# ATSAM4LC4A register map
Vendor: Atmel Corporation; Series: SAM4L; File version: B
CPU: CM4 r0p1, little endian, MPU, no FPU, 4 interrupt priority bits
Registers are 32-bit, write-only, reset 0x0 unless marked. A register's access mark holds for its fields unless they carry their own. Offsets are from the block's base; [hi:lo] are bit positions; {n}, {i} and the like mark numbered series.

## ABDACB — Audio Bitstream DAC
Base 0x40064000; register names take the prefix ABDACB_
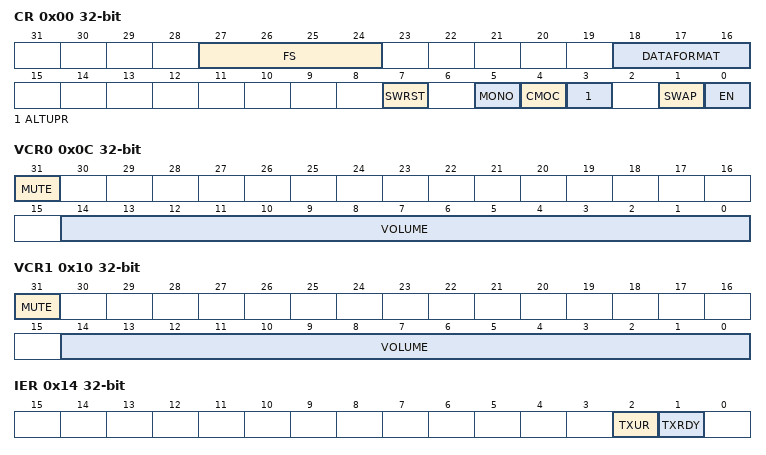
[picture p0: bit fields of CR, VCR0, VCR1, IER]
0x00 CR rw — Control Register
  [27:24] FS — Sampling frequency
  [18:16] DATAFORMAT — Data word format
  [7] SWRST — Software reset
  [5] MONO — Mono mode
  [4] CMOC — Common mode offset control
  [3] ALTUPR — Alternative up-sampling ratio
  [1] SWAP — Swap Channels
    0=The CHANNEL0 and CHANNEL1 samples will not be swapped when writing the Audio DAC Sample Data Register (SDR); 1=The CHANNEL0 and CHANNEL1 samples will be swapped when writing the Audio DAC Sample Data Register (SDR)
  [0] EN — Enable
    0=Audio DAC is disabled; 1=Audio DAC is enabled
0x04 SDR0 rw — Sample Data Register 0
  [31:0] DATA — Sample Data
0x08 SDR1 rw — Sample Data Register 1
  [31:0] DATA — Sample Data
0x0C VCR0 rw — Volume Control Register 0
  [31] MUTE
  [14:0] VOLUME — Volume Control
0x10 VCR1 rw — Volume Control Register 1
  [31] MUTE
  [14:0] VOLUME — Volume Control
0x14 IER — Interrupt Enable Register
  [2] TXUR — Transmit Underrun Interrupt Enable
    0=No effect; 1=Enables the Audio DAC Underrun interrupt
  [1] TXRDY — Transmit Ready Interrupt Enable
    0=No effect; 1=Enables the Audio DAC TX Ready interrupt
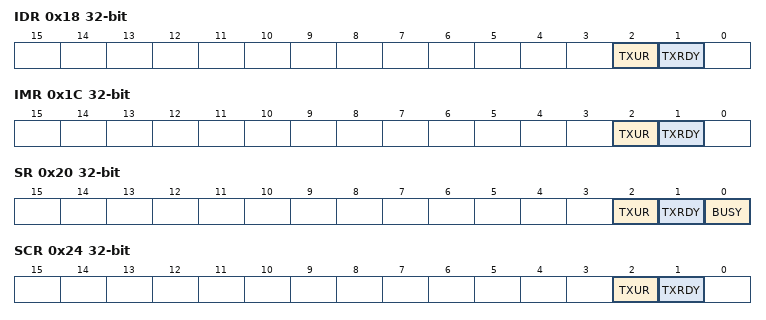
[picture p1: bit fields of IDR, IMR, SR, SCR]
0x18 IDR — Interupt Disable Register
  [2] TXUR — Transmit Underrun Interrupt Disable
    0=No effect; 1=Disable the Audio DAC Underrun interrupt
  [1] TXRDY — Transmit Ready Interrupt Disable
    0=No effect; 1=Disable the Audio DAC TX Ready interrupt
0x1C IMR ro — Interrupt Mask Register
  [2] TXUR — Transmit Underrun Interrupt Mask
    0=The Audio DAC Underrun interrupt is disabled; 1=The Audio DAC Underrun interrupt is enabled
  [1] TXRDY — Transmit Ready Interrupt Mask
    0=The Audio DAC TX Ready interrupt is disabled; 1=The Audio DAC TX Ready interrupt is enabled
0x20 SR ro — Status Register
  [2] TXUR — Transmit Underrun
    0=No Audio DAC Underrun has occured since the last time ISR was read or since reset; 1=At least one Audio DAC Underrun has occured since the last time ISR was read or since reset
  [1] TXRDY — Transmit Ready
    0=No Audio DAC TX Ready has occured since the last time ISR was read or since reset; 1=At least one Audio DAC TX Ready has occured since the last time ISR was read or since reset
  [0] BUSY — ABDACB Busy
0x24 SCR — Status Clear Register
  [2] TXUR — Transmit Underrun Interrupt Clear
    0=No effect; 1=Clear the Audio DAC Underrun interrupt
  [1] TXRDY — Transmit Ready Interrupt Clear
    0=No effect; 1=Clear the Audio DAC TX Ready interrupt
0x28 PARAMETER ro
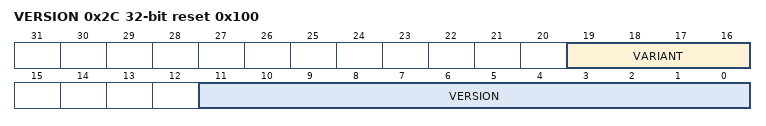
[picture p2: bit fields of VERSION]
0x2C VERSION ro reset 0x100
  [19:16] VARIANT — Variant Number
  [11:0] VERSION — Version Number

## ACIFC — Analog Comparator Interface
Base 0x40040000; register names take the prefix ACIFC_
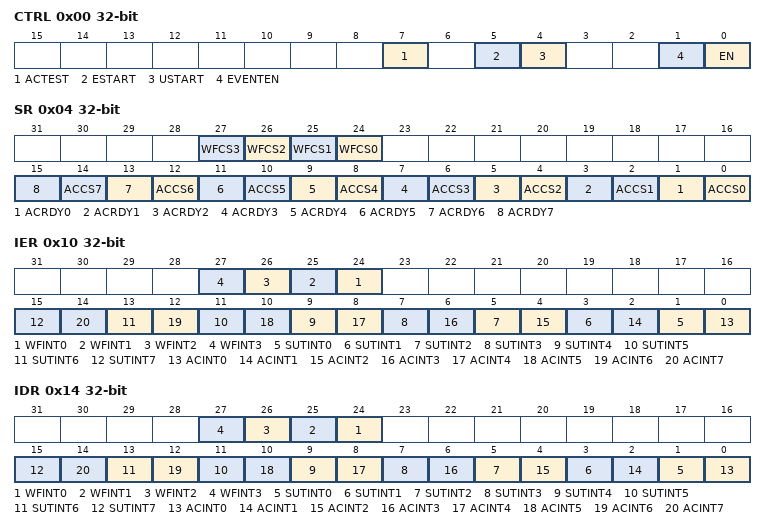
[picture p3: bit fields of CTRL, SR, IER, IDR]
0x00 CTRL rw — Control Register
  [7] ACTEST — Analog Comparator Test Mode
  [5] ESTART — Peripheral Event Start Single Comparison
  [4] USTART — User Start Single Comparison
  [1] EVENTEN — Peripheral Event Trigger Enable
  [0] EN — ACIFC Enable
0x04 SR ro — Status Register
  [n+24] WFCS{n} (n=0..3) — Window{n} Mode Current Status
  [2n+1] ACRDY{n} (n=0..7) — AC{n} Ready
  [2n] ACCS{n} (n=0..7) — AC{n} Current Comparison Status
0x10 IER — Interrupt Enable Register
  [n+24] WFINT{n} (n=0..3) — Window{n} Mode Interrupt Enable
  [2n+1] SUTINT{n} (n=0..7) — AC{n} Startup Time Interrupt Enable
  [2n] ACINT{n} (n=0..7) — AC{n} Interrupt Enable
0x14 IDR — Interrupt Disable Register
  [n+24] WFINT{n} (n=0..3) — Window{n} Mode Interrupt Disable
  [2n+1] SUTINT{n} (n=0..7) — AC{n} Startup Time Interrupt Disable
  [2n] ACINT{n} (n=0..7) — AC{n} Interrupt Disable
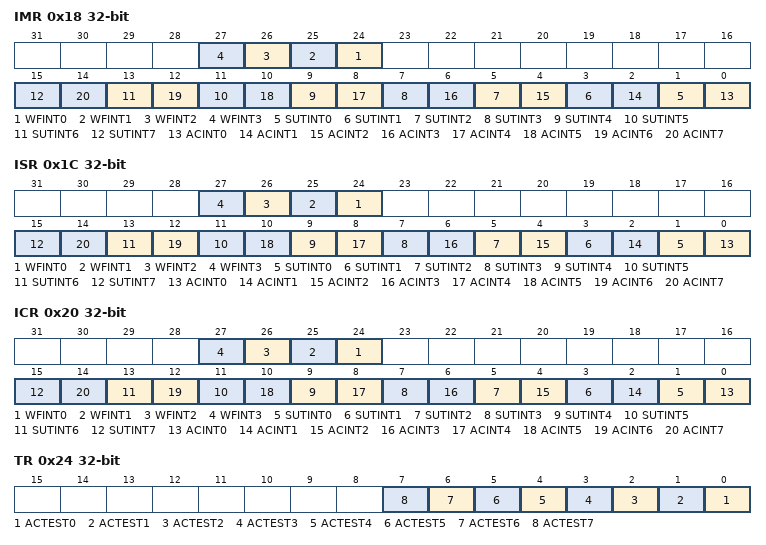
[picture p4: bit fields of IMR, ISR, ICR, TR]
0x18 IMR ro — Interrupt Mask Register
  [n+24] WFINT{n} (n=0..3) — Window{n} Mode Interrupt Mask
  [2n+1] SUTINT{n} (n=0..7) — AC{n} Startup Time Interrupt Mask
  [2n] ACINT{n} (n=0..7) — AC{n} Interrupt Mask
0x1C ISR ro — Interrupt Status Register
  [n+24] WFINT{n} (n=0..3) — Window{n} Mode Interrupt Status
  [2n+1] SUTINT{n} (n=0..7) — AC{n} Startup Time Interrupt Status
  [2n] ACINT{n} (n=0..7) — AC{n} Interrupt Status
0x20 ICR — Interrupt Status Clear Register
  [n+24] WFINT{n} (n=0..3) — Window{n} Mode Interrupt Status Clear
  [2n+1] SUTINT{n} (n=0..7) — AC{n} Startup Time Interrupt Status Clear
  [2n] ACINT{n} (n=0..7) — AC{n} Interrupt Status Clear
0x24 TR rw — Test Register
  [n] ACTEST{n} (n=0..7) — AC{n} Output Override Value
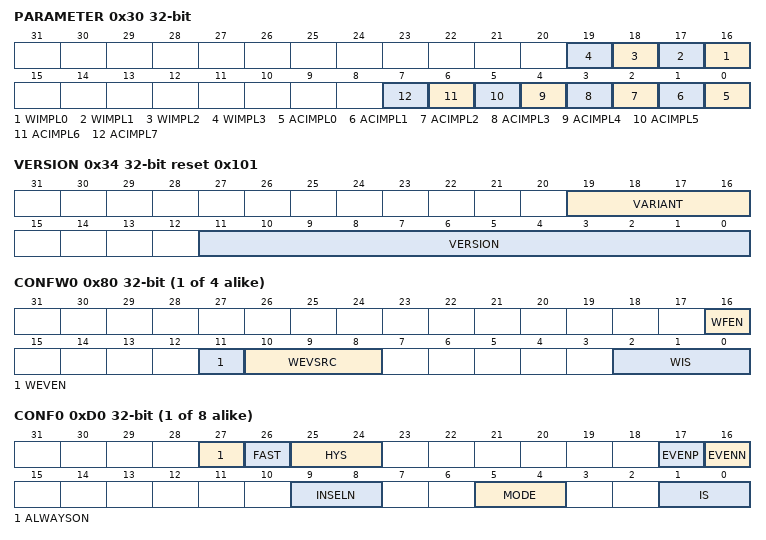
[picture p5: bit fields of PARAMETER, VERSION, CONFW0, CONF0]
0x30 PARAMETER ro
  [n+16] WIMPL{n} (n=0..3) — Window{n} Mode Implemented
  [n] ACIMPL{n} (n=0..7) — Analog Comparator {n} Implemented
0x34 VERSION ro reset 0x101
  [19:16] VARIANT — Variant Number
  [11:0] VERSION — Version Number
{0x80+4i} CONFW{i} (i=0..3) rw — Window configuration Register
  [16] WFEN — Window Mode Enable
  [11] WEVEN — Window Peripheral Event Enable
  [10:8] WEVSRC — Peripheral Event Sourse Selection for Window Mode
  [2:0] WIS — Window Mode Interrupt Settings
{0xD0+4i} CONF{i} (i=0..7) rw — AC Configuration Register
  [27] ALWAYSON
  [26] FAST — Fast Mode Enable
  [25:24] HYS — Hysteresis Voltage Value
  [17] EVENP — Peripheral Event Enable Positive
  [16] EVENN — Peripheral Event Enable Negative
  [9:8] INSELN — Negative Input Select
  [5:4] MODE — Analog Comparator Mode
  [1:0] IS — Interupt Settings

## Notices in the file
Atmel Microcontroller Software Support
Copyright (c) 2016 Atmel Corporation,
a wholly owned subsidiary of Microchip Technology Inc.
Licensed under the Apache License, Version 2.0 (the "License");
you may not use this file except in compliance with the License.
You may obtain a copy of the Licence at
http://www.apache.org/licenses/LICENSE-2.0
Unless required by applicable law or agreed to in writing, software
distributed under the License is distributed on an "AS IS" BASIS,
WITHOUT WARRANTIES OR CONDITIONS OF ANY KIND, either express or implied.
See the License for the specific language governing permissions and
limitations under the License.
